# EFR32FG1V131F256GM48 register map
File version: 3.0.0
Silicon Labs EFR32FG1V131F256GM48 Cortex-M MCU
CPU: CM4 r0p1, little endian, MPU, FPU, 3 interrupt priority bits
Registers are 32-bit, read-write, reset 0x0 unless marked. A register's access mark holds for its fields unless they carry their own. Offsets are from the block's base; lines under a group give offsets from that group; [hi:lo] are bit positions; {n}, {i} and the like mark numbered series; 'fields as' and 'values as' point back to an identical list; <NAME> marks a mode.

## Memory map
0x21000F00 SEQ size 0x100 — Sequencer
0x40000000 ACMP0 size 0x400
0x40000400 ACMP1 size 0x400
0x40002000 ADC0 size 0x400
0x40006000 IDAC0 size 0x400
0x4000A000 GPIO size 0x1000
0x4000C000 I2C0 size 0x400
0x40010000 USART0 size 0x400
0x40010400 USART1 size 0x400
0x40018000 TIMER0 size 0x400
0x40018400 TIMER1 size 0x400
0x4001C000 GPCRC size 0x400
0x4001E000 CRYOTIMER size 0x400
0x40042000 RTCC size 0x400
0x40046000 LETIMER0 size 0x400
0x4004A000 LEUART0 size 0x400
0x4004E000 PCNT0 size 0x400
0x40052000 WDOG0 size 0x400
0x40080000 FRC size 0x400 — Frame controller
0x40081000 BUFC size 0x400 — Buffer controller
0x40082000 CRC size 0x400 — RF CRC engine
0x40083000 SYNTH size 0x400 — Frequency synthezicer
0x40084000 RAC size 0x400 — Radio controller
0x40085000 PROTIMER size 0x400
0x40086000 MODEM size 0x800 — Modem controller
0x40087000 AGC size 0x400 — Auto gain controller
0x40088000 RFSENSE size 0x400
0x400E0000 MSC size 0x800
0x400E1000 FPUEH size 0x400
0x400E2000 LDMA size 0x1000
0x400E3000 EMU size 0x400
0x400E4000 CMU size 0x400
0x400E5000 RMU size 0x400
0x400E6000 PRS size 0x400
0x400F0000 CRYPTO size 0x400

## Interrupts
0 EMU
1 FRC_PRI (FRC)
2 WDOG0
3 FRC
4 MODEM
5 RAC_SEQ (RAC)
6 RAC_RSM (RAC)
7 BUFC
8 LDMA
9 GPIO_EVEN (GPIO)
10 TIMER0
11 USART0_RX (USART0)
12 USART0_TX (USART0)
13 ACMP0 (ACMP0, ACMP1)
14 ADC0
15 IDAC0
16 I2C0
17 GPIO_ODD (GPIO)
18 TIMER1
19 USART1_RX (USART1)
20 USART1_TX (USART1)
21 LEUART0
22 PCNT0
23 CMU
24 MSC
25 CRYPTO
26 LETIMER0
27 AGC
28 PROTIMER
29 RTCC
30 SYNTH
31 CRYOTIMER
32 RFSENSE
33 FPUEH

## Further device data
name=Copyright 2020 Silicon Laboratories, Inc., flashBaseAddress=0x00000000, flashSize=0x00040000, flashAccessTypes=rx, sramBaseAddress=0x20000000, sramSize=0x00008000, sramAccessTypes=rwx

## RMU
Base 0x400E5000
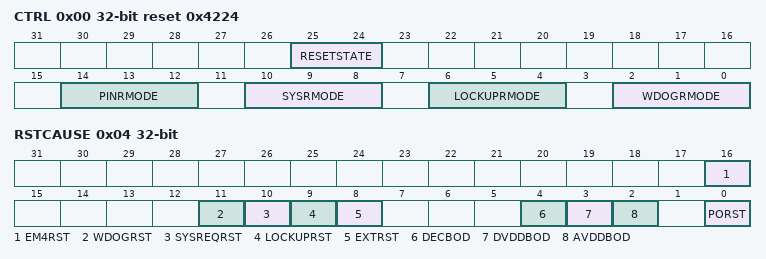
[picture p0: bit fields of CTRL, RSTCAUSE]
0x00 CTRL reset 0x4224 — Control Register
  [25:24] RESETSTATE — System Software Reset State
  [14:12] PINRMODE — PIN Reset Mode
    0=DISABLED (Reset request is blocked.); 1=LIMITED (The CRYOTIMER, DEBUGGER, RTCC, are not reset.); 2=EXTENDED (The CRYOTIMER, DEBUGGER are not reset. RTCC is reset.); 4=FULL (The entire device is reset except some EMU and RMU registers.)
  [10:8] SYSRMODE — Core Sysreset Reset Mode
    values as PINRMODE
  [6:4] LOCKUPRMODE — Core LOCKUP Reset Mode
    values as PINRMODE
  [2:0] WDOGRMODE — WDOG Reset Mode
    0=DISABLED (Reset request is blocked. This disable bit is redundant with enable/disable bit in WDOG); 1=LIMITED (The CRYOTIMER, DEBUGGER, RTCC, are not reset.); 2=EXTENDED (The CRYOTIMER, DEBUGGER are not reset. RTCC is reset.); 4=FULL (The entire device is reset except some EMU and RMU registers.)
0x04 RSTCAUSE ro — Reset Cause Register
  [16] EM4RST — EM4 Reset
  [11] WDOGRST — Watchdog Reset
  [10] SYSREQRST — System Request Reset
  [9] LOCKUPRST — LOCKUP Reset
  [8] EXTRST — External Pin Reset
  [4] DECBOD — Brown Out Detector Decouple Domain Reset
  [3] DVDDBOD — Brown Out Detector DVDD Reset
  [2] AVDDBOD — Brown Out Detector AVDD Reset
  [0] PORST — Power on Reset
0x08 CMD wo — Command Register
  [0] RCCLR — Reset Cause Clear
0x0C RST reset not defined — Reset Control Register
0x10 LOCK — Configuration Lock Register
  [15:0] LOCKKEY — Configuration Lock Key
    0=UNLOCKED; 1=LOCKED

## Licence text in the file
******************************************************************************* * # License * Copyright 2020 Silicon Laboratories Inc. www.silabs.com ******************************************************************************* * * SPDX-License-Identifier: Zlib * * The licensor of this software is Silicon Laboratories Inc. * * This software is provided 'as-is', without any express or implied * warranty. In no event will the authors be held liable for any damages * arising from the use of this software. * * Permission is granted to anyone to use this software for any purpose, * including commercial applications, and to alter it and redistribute it * freely, subject to the following restrictions: * * 1. The origin of this software must not be misrepresented; you must not * claim that you wrote the original software. If you use this software * in a product, an acknowledgment in the product documentation would be * appreciated but is not required. * 2. Altered source versions must be plainly marked as such, and must not be * misrepresented as being the original software. * 3. This notice may not be removed or altered from any source distribution. * *******************************************************************************
